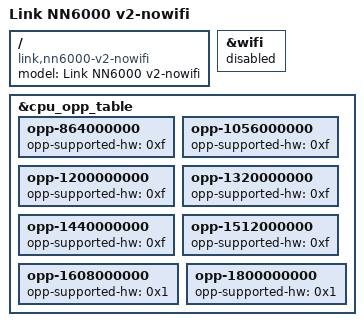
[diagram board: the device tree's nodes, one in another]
// SPDX-License-Identifier: GPL-2.0-or-later OR MIT

#include "ipq6000-nn6000-v2.dts"

/ {
	model = "Link NN6000 v2-nowifi";
	compatible = "link,nn6000-v2-nowifi", "link,nn6000-v2", "qcom,ipq6018";
};

&wifi {
	status = "disabled";
};

&cpu_opp_table {
	opp-864000000 {
		opp-supported-hw = <0xf>;
	};

	opp-1056000000 {
		opp-supported-hw = <0xf>;
	};

	opp-1200000000 {
		opp-supported-hw = <0xf>;
	};

	opp-1320000000 {
		opp-supported-hw = <0xf>;
	};

	opp-1440000000 {
		opp-supported-hw = <0xf>;
	};

	opp-1512000000 {
		opp-supported-hw = <0xf>;
	};

	opp-1608000000 {
		opp-supported-hw = <0x1>;
	};

	opp-1800000000 {
		opp-supported-hw = <0x1>;
	};
};
